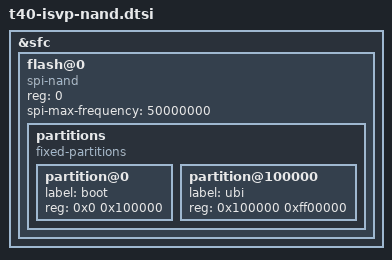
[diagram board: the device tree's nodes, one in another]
// SPDX-License-Identifier: GPL-2.0+
/*
 * Ingenic ISVP-T40 SFC-NAND boot-media fragment: the SPI-NAND flash
 * node + partition map on the SFC controller. Included by NAND-boot
 * leaf .dts files.
 */

&sfc {
	flash@0 {
		compatible = "spi-nand";
		reg = <0>;
		spi-max-frequency = <50000000>;

		partitions {
			compatible = "fixed-partitions";
			#address-cells = <1>;
			#size-cells = <1>;

			/*
			 * Layout (SPI-NAND, 256 MiB, 128 KiB erase block):
			 *   boot 1 MiB : raw SPL @ 0 + raw U-Boot @ 0x8000
			 *                (matches binman u-boot-with-spl-lzma.bin)
			 *   ubi  rest  : UBI container - holds uboot-env,
			 *                kernel (FIT), rootfs (squashfs), and
			 *                overlay (UBIFS) as named volumes.
			 * U-Boot env lives in the UBI volume "uboot-env"
			 * (CONFIG_ENV_IS_IN_UBI) so it survives bad blocks
			 * via UBI wear-leveling.
			 */
			partition@0 {
				label = "boot";
				reg = <0x0 0x100000>;
			};

			partition@100000 {
				label = "ubi";
				reg = <0x100000 0xff00000>;
			};
		};
	};
};
